# TC37XPD register map
Vendor: Infineon; Series: ATVMC; File version: 100
CPU: other r0p0, little endian, MPU, FPU, vendor SysTick, 4 interrupt priority bits
Registers are 32-bit, read-write, reset 0x0 unless marked. A register's access mark holds for its fields unless they carry their own. Offsets are from the block's base; [hi:lo] are bit positions; lines under a group give offsets from that group; {n}, {i} and the like mark numbered series; 'fields as' and 'values as' point back to an identical list.

## PSI5 (part 1 of 2)
Base 0xF0005000
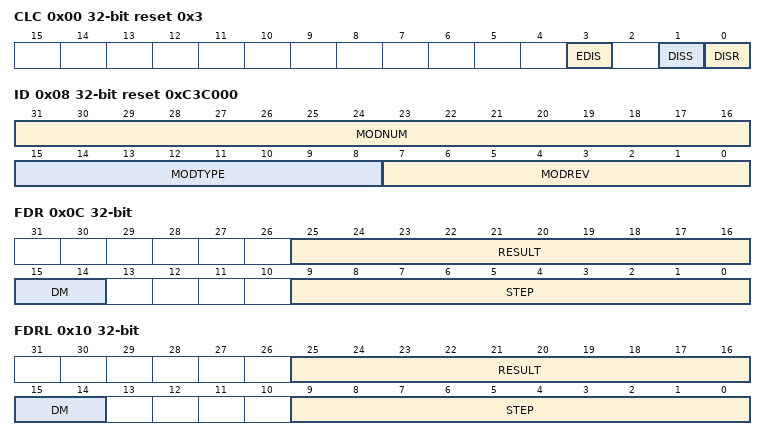
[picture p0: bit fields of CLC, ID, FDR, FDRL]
0x00 CLC access per field reset 0x3 — Clock Control Register resetvalue={Application Reset:0x3}
  [3] EDIS rw — External Sleep Mode Request Disable Bit EDIS. Used to control module s sleep mode. If this bit is cleared the kernel clock f PSI5 is disabled during System Sleep Mode.
  [1] DISS ro — Module Disable Status Bit DISS. Bit indicates the current status of the module.
  [0] DISR rw — Module Disable Request Bit DISR. Used for enable disable control of the module.
0x08 ID ro reset 0xC3C000 (reset mask 0xFFFFFF00) — Module Identification Register resetvalue={Application Reset:0x0C3C000}
  [31:16] MODNUM — Module Number Value MODNUM. This bit field defines the module identification number for the PSI5 00C3 H
  [15:8] MODTYPE — Module Type MODTYPE. This bit field defines the module as a 32 bit module C0 H
  [7:0] MODREV — Module Revision Number MODREV. This bit field defines the module revision number. The value of a module revision starts with 01 H first revision .
0x0C FDR access per field — PSI5 Fractional Divider Register resetvalue={Application Reset:0x0}
  [25:16] RESULT ro — Result Value RESULT. Bit field for the addition result.
  [15:14] DM rw — Divider Mode DM. DM selects normal or fractional divider mode.
  [9:0] STEP rw — Step Value STEP. Reload or addition value for RESULT.
0x10 FDRL access per field — Fractional Divider Register for Lower Bit Rate resetvalue={Application Reset:0x0}
  fields as FDR
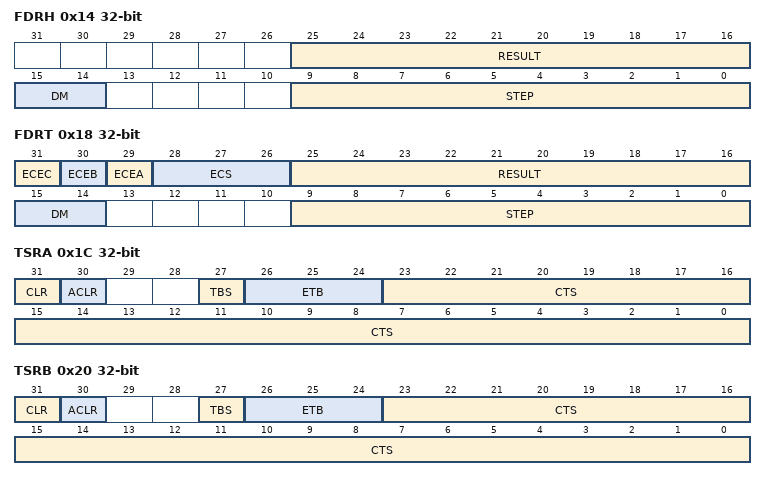
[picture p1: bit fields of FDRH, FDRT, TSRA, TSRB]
0x14 FDRH access per field — Fractional Divider Register for Higher Bit Rate resetvalue={Application Reset:0x0}
  fields as FDR
0x18 FDRT access per field — Fractional Divider Register for Time Stamp resetvalue={Application Reset:0x0}
  [31] ECEC rw — External Time Stamp Clear Enable C ECEC. Enables the external trigger line selected by ECS to clear the global time stamp counter TSRC.CTS on rising edge of the external trigger.
  [30] ECEB rw — External Time Stamp Clear Enable B ECEB. Enables the external trigger line selected by ECS to clear the global time stamp counter TSRB.CTS on rising edge of the external trigger.
  [29] ECEA rw — External Time Stamp Clear Enable A ECEA. Enables the external trigger line selected by ECS to clear the global time stamp counter TSRA.CTS on rising edge of the external trigger.
  [28:26] ECS rw — External Time Stamp Clear Source Select ECS. Selects the external trigger line that clears the global time stamp counters TSRA B C.CTS if this is enabled by ECEA ECEB ECEC. Channel must be disabled if changed GCR.CEN 0 .
  [25:16] RESULT ro — Result Value RESULT. Bit field for the addition result.
  [15:14] DM rw — Divider Mode DM. DM selects normal or fractional divider mode.
  [9:0] STEP rw — Step Value STEP. Reload or addition value for RESULT.
0x1C TSRA access per field — Module Time Stamp Register A resetvalue={Application Reset:0x0}
  [31] CLR wo — Clear Current Time Stamp for the Module CLR. If set this bit clears CTS. CTS counts on starting from 0. This bit is automatically cleared by HW and will always be read as zero.
  [30] ACLR wo — Clear All Current Time Stamp Counters ACLR. If set this bit clears TSRA B C.CTS. TSRA B C.CTS count on starting from 0. This bit is automatically cleared by HW and will always be read as zero.
  [27] TBS rw — Time Base Select TBS. This bit selects the clock source for CTS
  [26:24] ETB rw — External Time Base Select ETB. Selects the external clock line for counter CTS. Channel must be disabled if changed GCR.CEN 0 .
  [23:0] CTS ro — Current Time Stamp for the Module CTS. This bit field shows the current time stamp.
0x20 TSRB access per field — Time Stamp Register B resetvalue={Application Reset:0x0}
  fields as TSRA
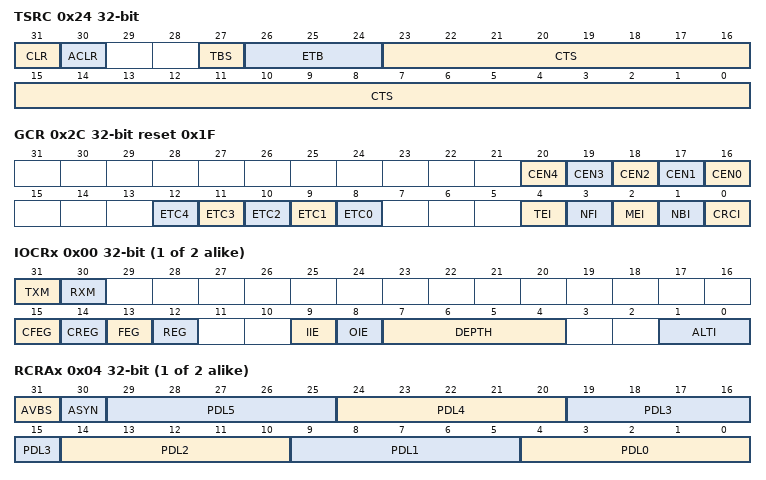
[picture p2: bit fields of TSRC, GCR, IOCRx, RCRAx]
0x24 TSRC access per field — Module Time Stamp Register C resetvalue={Application Reset:0x0}
  fields as TSRA
0x2C GCR reset 0x1F — Global Control Register resetvalue={Application Reset:0x1F}
  [n+16] CEN{n} (n=0..4) — Enable Channel CEN4. This bit enables PSI5 Channel x. If cleared all internal state machines of the receiver and the sender are forced to default idle state while all registers can be read and written. Used for configuration of a channel. In the device only CEN0 4 are available. All other must be written with 0 and always read 0.
  [n+8] ETC{n} (n=0..4) — Enable Channel Trigger Counter CTV4.CTC ETC4. This bit enables CTVx.CTC. The bits ETC0 ..x can be set with one write access to synchronously start all counters. This is required for proper sync pulse staggering. If set CTCx counts on starting from its current value. CTCx can be written only if ETCx is cleared stopped . In the device only ETC0 4 are available. All other must be written with 0 and always read 0.
  [4] TEI — TEI TEI. is selected if bit is set.
  [3] NFI — NFI NFI. is selected if bit is set.
  [2] MEI — MEI MEI. is selected if bit is set.
  [1] NBI — NBI NBI. is selected if bit is set.
  [0] CRCI — CRCI CRCI. is selected if bit is set.
{0x30+0x90*i} CH[{i}] (i=0..1) group
  0x00 IOCRx access per field — Input and Output Control Register 0 resetvalue={Application Reset:0x0}
    [31] TXM ro — Transmit Monitor for Channel x TXM. Shows the status of the transmit signal of channel x inverted as specified by OIE.
    [30] RXM ro — Receive Monitor for Channel x RXM. Shows the status of the receive signal of channel x after glitch filtering and inverted as specified by IIE.
    [15] CFEG wo — Clear Falling Edge Glitch Flag for Channel x CFEG. Clears the status flag FEG CFEG always read zero.
    [14] CREG wo — Clear Rising Edge Glitch Flag for Channel x CREG. Clears the status flag REG CREG always read zero.
    [13] FEG ro — Falling Edge Glitch Flag for Channel x FEG. Shows the status of the glitch detection of channel x FEG is cleared by setting CFEG.
    [12] REG ro — Rising Edge Glitch Flag for Channel x REG. Shows the status of the glitch detection of channel x REG is cleared by setting CREG.
    [9] IIE rw — Input Inverter Enable Channel x IIE. Selects the Pulse Polarity of the input of channel x
    [8] OIE rw — Output Inverter Enable Channel x OIE. Selects the Pulse Polarity of the output of channel x
    [7:4] DEPTH rw — Digital Glitch Filter Depth DEPTH. DEPTH determines the number of port input samples clocked with f PSI5 that are taken into account for the calculation of the floating average. The higher DEPTH is chosen to be the longer the glitches that are suppressed and the longer the delay of the input signal introduced by this filter.
    [1:0] ALTI rw — Alternate Input Select ALTI. Selects the alternate input for channel x
  0x04 RCRAx — Receiver Control Register A 0 resetvalue={Application Reset:0x0}
    [31] AVBS — Verbose Mode for Asynchronous Mode AVBS. If set and ASYN is set and WDL0 is gt 0 an empty frame is stored in RDRL Hx and the referring RDML H each time the watch dog timer for the PSI5 channel x without reception of a frame.
    [30] ASYN — Asynchronous Mode ASYN. If set the watch dog timers for the PSI5 channel x slot WDL1 .. 6 are disabled If WDL0 is not cleared TEI is issued if the distance between two frames is longer than specified in WDL0 Slot Counter SC is incremented with each received frame works as frame counter with roll over after 6. No Sync Pulses generated TX path is inactive Note that in Asynchronous Mode all slow channel data is still collected in Slot 1 SDSx0 .
    [5n+4:5n] PDL{n} (n=0..5) — Payload Data Length PDL5. PDL determines the number of data bits per frame that the PSI5 channel x is setup for in slot y. PDL does not include the start bits and the Parity CRC bits. PDL includes the Messaging bits the Frame Control bits and the Status bits.
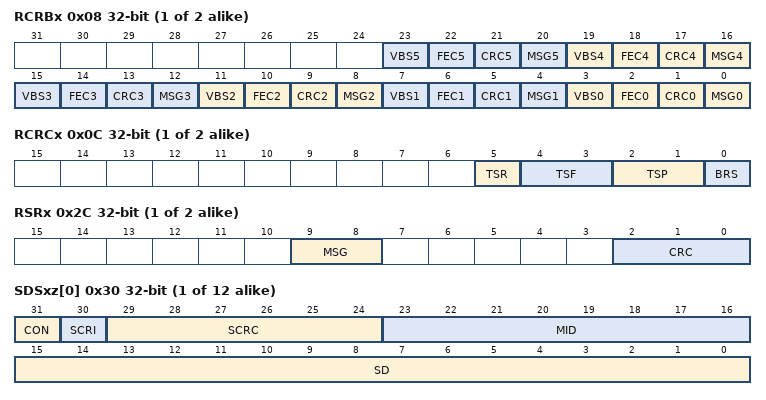
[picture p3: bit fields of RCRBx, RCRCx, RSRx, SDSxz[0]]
  0x08 RCRBx — Receiver Control Register B 0 resetvalue={Application Reset:0x0}
    [4n+3] VBS{n} (n=0..5) — Verbose Mode VBS5. If set and a message is expected for the PSI5 channel x in slot y FECy an empty frame is stored in RDRL Hx and the referring RDML H each time the watch dog timer for the PSI5 channel x slot y expires without reception of a frame.
    [4n+2] FEC{n} (n=0..5) — Frame Expectation Control FEC5. If set a frame is expected for the PSI5 channel x in slot y. A No Frame Received error interrupt NFI is issued each time the watch dog timer for the PSI5 channel x slot y expires without reception of a SOF or EOF.
    [4n+1] CRC{n} (n=0..5) — CRC or Parit5 Selection CRC5. If set a 3 bit CRC checksum is expected for the PSI5 channel x in slot y. Else 1 bit Parity is assumed.
    [4n] MSG{n} (n=0..5) — Messaging Bits MSG5. If set the 2 Messaging bits are configured for the PSI5 channel x in slot y. If set Enhanced Serial Message processing on bits D 1 0 is activated. 18 frames 4 or 8 bit ID 12 or 16 bit data 6 bit CRC If Messaging bits are transmitted they are always presented in RDRx independently from status of MSGy. I.e. RDRx always stores exactly the data that was received.
  0x0C RCRCx — Receiver Control Register C 0 resetvalue={Application Reset:0x0}
    [5] TSR — Time Stamp Select for Receive Data Registers TSR
    [4:3] TSF — Time Stamp Select for Start of Frame SOF TSF
    [2:1] TSP — Time Stamp Select for Pulses TSP
    [0] BRS — Bit Rate Select BRS
  {0x10+4j} WDTxw[{j}] (j=0..6) — Watch Dog Timer Register 00 resetvalue={Application Reset:0x0}
    [15:0] WDL — Watch Dog Timer Limit WDL. for channel x limit w.
  0x2C RSRx ro — Receive Status Register 0 resetvalue={Application Reset:0x0}
    [9:8] MSG — Messaging Bits MSG. of last frame. MSG0 is on bit position 8.
    [2:0] CRC — CRC CRC. of last frame. CRC0 is on bit position 0.
  {0x30+4j} SDSxz[{j}] (j=0..5) ro — Serial Data and Status Register 00 resetvalue={Application Reset:0x0}
    [31] CON — Configuration bit CON. of last serial frame.
    [30] SCRI — CRC of Serial Message failed Interrupt Flag. SCRI. This bit is set if the CRC of the serial message fails. This includes a check of the Messaging bit field for correct 0 values of bit 1 in frames 7 13 and 18. See INTSTATx.
    [29:24] SCRC — SCRC SCRC. CRC of last serial data frame. CRC0 is on position 24.
    [23:16] MID — Message ID MID. of last serial data frame. ID0 is on bit position 16. If SDS.CON is set bits 23 20 are zero.
    [15:0] SD — Serial Data SD. of last serial data frame on channel x slot z. SD0 is on bit position 0. If SDS.CON is not set bits 15 12 are zero.
  0x48 SPTSCx ro — Start of Pulse Time Stamp Capture Register 0 resetvalue={Application Reset:0x0}
    [23:0] TS — Time Stamp TS. of the last sync pulse sent on channel x. The Time Stamp is taken at the rising edge of the pulse.
  0x4C SFTSCx ro — Start of Frame Time Stamp Capture Register 0 resetvalue={Application Reset:0x0}
    [23:0] TS — Time Stamp TS. of the last frame received on channel x. The Time Stamp is taken at the rising edge of the first start bit S1 that was qualified by the receiver.
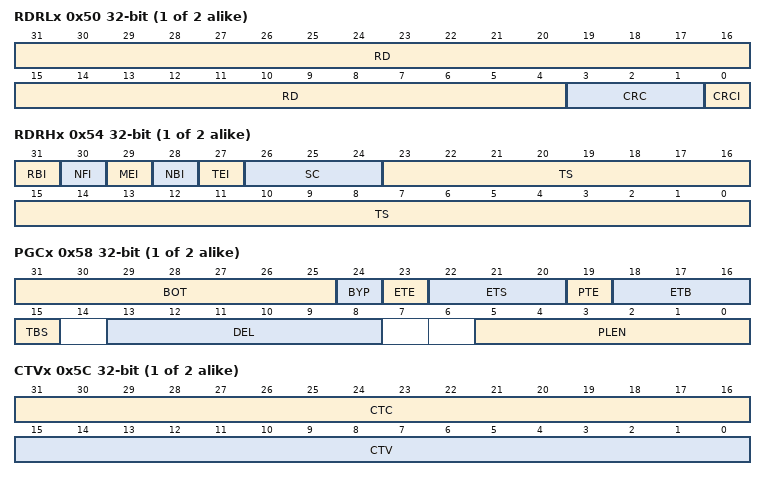
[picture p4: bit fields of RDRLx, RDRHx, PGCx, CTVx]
  0x50 RDRLx ro — Receive Data Register Low 0 resetvalue={Application Reset:0x0}
    [31:4] RD — RD RD. Receive data of last PSI5 frame. D0 is on bit position 4. In case of NFI this field is cleared.
    [3:1] CRC — CRC CRC. CRC parity bit of last PSI5 frame. CRC0 or Parity bit is on bit position 1. In case of NFI this field is cleared.
    [0] CRCI — CRC Error Flag CRCI. This bit is set if the CRC or Parity check fails. Set as well if CRC can not be calculated PDL 0 CRC cut off by Manchester Error too few bits BOT Sync Pulse
  0x54 RDRHx ro — Receive Data Register High 0 resetvalue={Application Reset:0x0}
    [31] RBI — Receive Buffer Overflow Flag RBI. This bit is set after a frame has been received while the old one was not read from RDRHx. I.e. the kernel wants to set any of the two interrupts RSI and RDI and finds any of these two interrupts already set. The old data is overwritten by the new data.
    [30] NFI — No Frame Received Flag NFI. This bit is set when the NFI condition as described in the first paragraph of INTSTATA.NFI occurs. If only the two start bits are received and no further data this x201c SOF x201d is discarded completely and treated like no frame received as well. If RCRBx.VBS is set an empty frame is stored anyhow and RDIx is issued as well. The content of RDRL Hx RDML Hx is valid for SC and for this bit NFI . Bit fields RD and CRC are cleared all zero . If RCRC.VBSx is 0 then TS is cleared. If RCRC.VBSx is 1 then TS is set to either SPTSCx.TS or SFTSCx.TS depending on the value of RCRC.TSR.
    [29] MEI — Error in Message Bits Flag MEI. This bit is set if a manchester error occurred in Bit M0 or M1. Only if configured in RCRBx.MSG Note that the frame after the error might be completely wrong.
    [28] NBI — Number of bits Error Flag NBI. This bit is set if the last frame received less bits than expected but no manchester coding error occurred until S1 S2 M0 and M1 where received. Note that the frame after the error might be completely wrong.
    [27] TEI — Time Slot Error Flag TEI. In Synchronous Mode RCRAx.ASYN 0 this bit is set if the SOF and the EOF of a frame are received in different time slots. The slots are constraint by the watch dog timer see WDTxy . In Asynchronous Mode RCRAx.ASYN 1 this bit is set if the distance between two frames is longer than specified in WDL0.
    [26:24] SC — Slot Counter SC. In Synchronous Mode RCRAx.ASYN 0 Number of the slot the SOF of the frame was received in. In Asynchronous Mode RCRAx.ASYN 1 revolving frame number between 1 and 6. Note that in Asynchronous Mode all slow channel data is still collected in Slot 1 SDSx0 .
    [23:0] TS — Time Stamp TS. of the last received PSI5 frame. RCRC.TSR determines if SPTSCx or SFTSCx is stored in RDRHx. It can be selected if the time stamp of the last sync pulse is stored or the time stamp for the start of frame .
  0x58 PGCx — Pulse Generation Control Register 0 resetvalue={Application Reset:0x0}
    [31:25] BOT — Blank Out Time BOT. BOT defines the length of the blank out time in TTS times defined by FDRT starting from the end of a Sync Pulse. The receiver is always switched off starting from the beginning of a Sync Pulse. BOT keeps the receiver switched off additionally after the Sync Pulse. This suppresses potential noise on the receive line after the pulse and thus eases the design of the transceiver.
    [24] BYP — Bypass Enable BYP. An external signal selected by ETS directly drives the output of channel x. Should be 0 if PTE or ETE is set.
    [23] ETE — External Trigger Enable ETE. 8220 Angle sync. trigger 8221 external line is selected by ETS. Should be 0 if PTE or BYP is set.
    [22:20] ETS — External Trigger Select ETS. Selects the external trigger line for pulse generation e.g. angle synchronous .
    [19] PTE — Periodic Trigger Enable PTE. Periodic trigger is defined by CTVx. Should be 0 if ETE or BYP is set.
    [18:16] ETB — External Time Base Select ETB. Selects the external clock line for counter CTVx.
    [15] TBS — Time Base Select TBS. This bit selects the clock source for CTVx
    [13:8] DEL — Delay Length DEL. In case data is coded into the pulse length this defines the ADDITONAL length of the pulse in TTS times. The resulting sum length is the pulse width for coding a 8216 1 8217 into the pulse width.
    [5:0] PLEN — Pulse Length PLEN. Defines the length of the pulse in TTS times defined by FDRT . This is the standard pulse width without data coding into the pulse width or for coding a 8216 0 8217 .
  0x5C CTVx — Channel Trigger Value Register 0 resetvalue={Application Reset:0x0}
    [31:16] CTC — Channel Trigger Counter CTC. This bit field allows to read the current counter value of the reset timer cell CTVx. If GCR.ETCx is cleared CTC can be written.
    [15:0] CTV — Channel Trigger Value CTV CTV. Contains the compare value exact match of Channel Trigger CTC at which a sync pulse is triggered for channel x and the counter CTC is cleared. If cleared CTC is stopped and no pulse is generated.
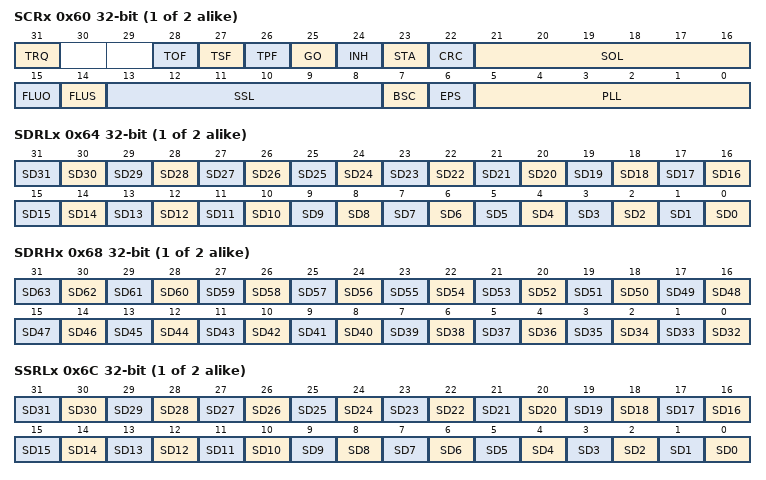
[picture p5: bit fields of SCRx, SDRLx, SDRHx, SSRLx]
  0x60 SCRx access per field — Send Control Register 0 resetvalue={Application Reset:0x0}
    [31] TRQ ro — Transfer Request in Progress TRQ. While a transfer is being sent this bit is set. Write access is ignored.
    [28] TOF ro — Transmit Output Flag TOF. If set data in SORL H is waiting to be transmitted to the sensor. This can be caused by an automatic transfer from SSRL H or from a CPU write access to SORL H. If SOL lt 32 it is sufficient to write SORL. Else only writing SDRH will set TSF. If set write access to SORL H will not change any data and issue TOOI. It is cleared automatically after data was transmitted to the sensor or after flushing the register by setting bit FLUO.
    [27] TSF ro — Transmit Shift Flag TSF. If set data in SSRL H is waiting to be shifted to SORL H. This can be caused by an automatic transfer from SDRL H or from a CPU write access to SSRL H. If SSL lt 32 it is sufficient to write SSRL. Else only writing SSRH will set TSF. If set write access to SSRL H will not change any data and issue TSOI. It is cleared automatically after data was shifted to SORL H or after flushing the register by setting bit FLUS.
    [26] TPF ro — Transmit Preparation Flag TPF. If set preparation is in progress start sequence and or CRC and or stuffing and or at least copying data from SDRL H. If set write access to SDRL H will not change any data and issue TPOI. It is cleared automatically after preparation is finished.
    [25] GO wo — Release prepared Send data GO. This is only relevant if INH is set It allows for manual control of the transfer from SSRH L to SORL H. It is always read as zero and is automatically cleared.
    [24] INH rw — Inhibit Transfer INH. This inhibits the automatic transfer from the shift registers SSRL H to SORL H after the preparation of all automatic bit fields STA BSC CRC . After a write access to SDRL Hx the automatic preparation is done by HW if selected. If automatic preparation of the start sequence is not selected data is moved by HW without change to SSRL H. When the HW is done with the transfer to the internal shift registers interrupt TPI is activated flag TSF is set and flag TPF is cleared automatically. Depending on INH GO must be set after TPI before transfer to SORL H takes place After the transfer to SORL H TSI is activated TOF is set and and TSF is cleared automatically. . INH defines the start mode
    [23] STA rw — Start Sequence Generation Control STA
    [22] CRC rw — CRC Generation Control CRC
    [21:16] SOL rw — Pay Load Length of Registers SORL H SOL. If SOL gt 31 SORH needs to be written to trigger the HW for automatic moving data to the pulse generator. Else writing to SORL is sufficient. SOL needs to written before SORL H is used for proper operation. Defines the length that is taken into account. Start Sequence CRC and Stuffing needs to be added by SW to PLL if SOL is calculated based on PLL.
    [15] FLUO wo — Flush SORH Lx FLUO. Setting this bit stops the sending process and flushes clears SORH Lx and TOF. TSIx is issued at the end of successful flushing. Reads always as zero.
    [14] FLUS wo — Flush SSRH Lx FLUS. Setting this bit stops the shifting process and flushes clears SSRH Lx and TSF. TPIx is issued at the end of successful flushing. Reads always as zero.
    [13:8] SSL rw — Pay Load Length of Registers SSRL H SSL. If SSL gt 31 SSRH needs to be written to trigger the HW for automatic moving data to SORL H. Else writing to SSRL is sufficient. SSL needs to be written before SSRL H is used for proper operation. Defines the length that is taken into account. Start Sequence BSC and CRC need to be added to PLL by SW if SSL is calculated based on PLL.
    [7] BSC rw — Bit Stuffing Control BSC. Depending from bit EPS after 3 bits a 8216 1 8217 is inserted V1.3 or after 6 bits a 8216 0 8217 is inserted enhanced Power Train Mode Note that this makes the frame longer.
    [6] EPS rw — Enhanced Protocol Selection EPS
    [5:0] PLL rw — Pay Load Length of Registers SDRL H PLL. If PLL gt 31 SDRH needs to be written to trigger the HW for automatic STA BSC or CRC generation or just moving data to SSRL H. Else writing to SDRL is sufficient. PLL needs to written before SDRL H is used for proper operation. If insertion of STA BSC and CRC results in more than 64 bits the MSBs are truncated in SSR. Defines the length that is taken into account
  0x64 SDRLx — Send Data Register Low 0 resetvalue={Application Reset:0x0}
    [n] SD{n} (n=0..31) — SD31 SD31. Send data of next ECU to Sensor frame. The unused MSBs bit position SCRx.PLL and higher must be written with 0 . If PLL is lt 32 SDRHx must not be written.
  0x68 SDRHx — Send Data Register High 0 resetvalue={Application Reset:0x0}
    [n-32] SD{n} (n=32..63) — SD63 SD63. Send data of next ECU to Sensor frame. The unused MSBs bit position SCRx.PLL and higher must be written with 8216 0 8217 . If PLL is lt 32 SDRHx must not be written.
  0x6C SSRLx — Send Shift Register Low 0 resetvalue={Application Reset:0x0}
    [n] SD{n} (n=0..31) — SD31 SD31. Send data of next ECU to Sensor frame. The sequence is STS AD SD CRC. Depending on individual field length the bit stream is continued in SSRHx.
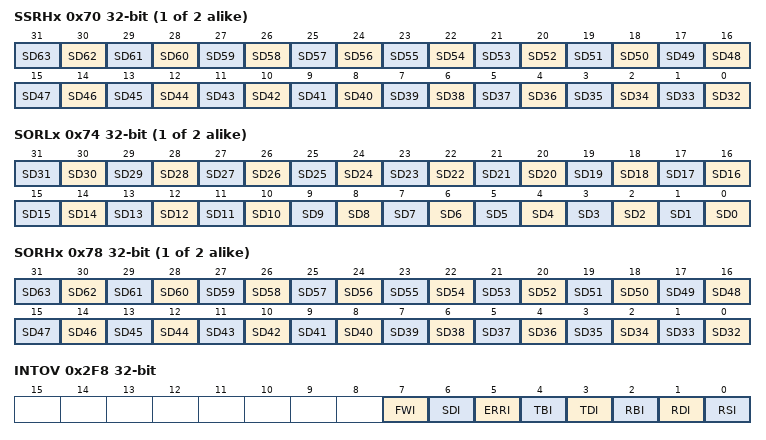
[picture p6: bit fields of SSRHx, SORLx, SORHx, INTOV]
  0x70 SSRHx — Send Shift Register High 0 resetvalue={Application Reset:0x0}
    [n-32] SD{n} (n=32..63) — SD63 SD63. Continues the bit stream as described in SSRLx.
  0x74 SORLx — Send Output Register Low 0 resetvalue={Application Reset:0x0}
    [n] SD{n} (n=0..31) — SD31 SD31. Send data of next ECU to Sensor frame. The sequence is STS AD SD CRC. Depending on individual field length the bit stream is continued in SORHx.
  0x78 SORHx — Send Output Register High 0 resetvalue={Application Reset:0x0}
    [n-32] SD{n} (n=32..63) — SD63 SD63. Continues the bit stream as described in SORLx.
0x2F8 INTOV ro — Interrupt Overview Register resetvalue={Application Reset:0x0}
  [7] FWI — Interrupt Pending on any Node Pointer FWI FWI. If any interrupt requested flag is set for any Node Pointer FWI in register INTSTATx AND the referring interrupt is enabled in INTENx then INTOV.FWI is set. It is automatically reset if all flags in INTSTATx are cleared for which the referring interrupt is enabled in INTENx.
  [6] SDI — Interrupt Pending on any Node Pointer SDI SDI. If any interrupt requested flag is set for any Node Pointer SDI in register INTSTATx AND the referring interrupt is enabled in INTENx then INTOV.SDI is set. It is automatically reset if all flags in INTSTATx are cleared for which the referring interrupt is enabled in INTENx.
  [5] ERRI — Interrupt Pending on any Node Pointer ERRI ERRI. If any interrupt requested flag is set for any Node Pointer ERRI in register INTSTATx AND the referring interrupt is enabled in INTENx then INTOV.ERRI is set. It is automatically reset if all flags in INTSTATx are cleared for which the referring interrupt is enabled in INTENx.
  [4] TBI — Interrupt Pending on any Node Pointer TBI TBI. If any interrupt requested flag is set for any Node Pointer TBI in register INTSTATx AND the referring interrupt is enabled in INTENx then INTOV.TBI is set. It is automatically reset if all flags in INTSTATx are cleared for which the referring interrupt is enabled in INTENx.
  [3] TDI — Interrupt Pending on any Node Pointer TDI TDI. If any interrupt requested flag is set for any Node Pointer TDI in register INTSTATx AND the referring interrupt is enabled in INTENx then INTOV.TDI is set. It is automatically reset if all flags in INTSTATx are cleared for which the referring interrupt is enabled in INTENx.
  [2] RBI — Interrupt Pending on any Node Pointer RBI RBI. If any interrupt requested flag is set for any Node Pointer RBI in register INTSTATx AND the referring interrupt is enabled in INTENx then INTOV.RBI is set. It is automatically reset if all flags in INTSTATx are cleared for which the referring interrupt is enabled in INTENx.
  [1] RDI — Interrupt Pending on any Node Pointer RDI RDI. If any interrupt requested flag is set for any Node Pointer RDI in register INTSTATx AND the referring interrupt is enabled in INTENx then INTOV.RDI is set. It is automatically reset if all flags in INTSTATx are cleared for which the referring interrupt is enabled in INTENx.
  [0] RSI — Interrupt Pending on any Node Pointer RSI RSI. If any interrupt requested flag is set for any Node Pointer RSI in register INTSTATx AND the referring interrupt is enabled in INTENx then INTOV.RSI is set. It is automatically reset if all flags in INTSTATx are cleared for which the referring interrupt is enabled in INTENx.
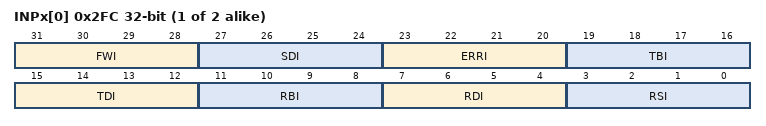
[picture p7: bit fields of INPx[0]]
{0x2FC+4i} INPx[{i}] (i=0..1) — Interrupt Node Pointer Register 0 resetvalue={Application Reset:0x0}
  [31:28] FWI — Interrupt Node Pointer for FWI FWI. This bit field defines the interrupt node that is requested due to the set condition for bit INTSTATx.FWI. For bit field definition see RSI.
  [27:24] SDI — Interrupt Node Pointer for Interrupt SDI SDI. This bit field defines the interrupt node that is requested due to the set condition for bit INTSTATx.SDI if enabled by bit INTENx.SDI . For bit field definition see RSI.
  [23:20] ERRI — Interrupt Node Pointer for Interrupt ERRI ERRI. This bit field defines the interrupt node that is requested due to the set condition for bit TEI NFI NBI MEI CRCI RUI RMI CRCIy WSIy SOIy SCRIy. For bit field definition see RSI.
  [19:16] TBI — Interrupt Node Pointer for Interrupt TBI TBI. This bit field defines the interrupt node that is requested due to the set condition for bit INTSTATAx.TPOI TSOI TOOI if enabled by bit INTENAx.TPOI TSOI TOOI . For bit field definition see RSI.
  [15:12] TDI — Interrupt Node Pointer for Interrupt TDI TDI. This bit field defines the interrupt node that is requested due to the set condition for bit INTSTATAx.TPI TSI TOI if enabled by bit INTENAx.TPI TSI TOI . For bit field definition see RSI.
  [11:8] RBI — Interrupt Node Pointer for Interrupt RBI RBI. This bit field defines the interrupt node that is requested due to the set condition for bit INTSTATAx.RBI if enabled by bit INTENAx.RBI . For bit field definition see RSI.
  [7:4] RDI — Interrupt Node Pointer for Interrupt RDI RDI. This bit field defines the interrupt node that is requested due to the set condition for bit INTSTATAx.RDI if enabled by bit INTENAx.RDI . For bit field definition see RSI.
  [3:0] RSI — Interrupt Node Pointer for Interrupt RSI RSI. This bit field defines the interrupt node that is requested due to the set condition for bit INTSTATAx.RSI if enabled by bit INTENAx.RSI .
